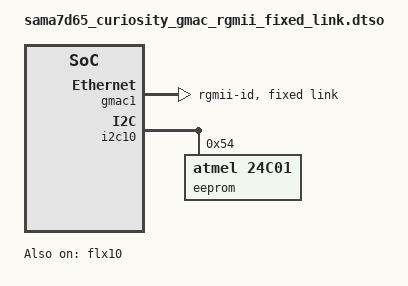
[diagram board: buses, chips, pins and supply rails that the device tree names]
// SPDX-License-Identifier: (GPL-2.0+ OR MIT)
/*
 *  Device Tree overlay for SAMA7D65-CURIOSITY board
 *  in order to use single-port Gigabit PHY EDS2 daughter card.
 *
 *  Copyright (c) 2026 Microchip Technology Inc. and its subsidiaries
 *
 *  Author: Joemel John Diente <joemeljohn.diente@microchip.com>
 *
 * Refer to the EV12N54A (LAN8840-EDS2 daughter card)
 *
 */
/dts-v1/;
/plugin/;
#include "sama7d65-pinfunc.h"
#include <dt-bindings/mfd/atmel-flexcom.h>
#include <dt-bindings/clock/at91.h>
#include <dt-bindings/pinctrl/at91.h>
#include <dt-bindings/gpio/gpio.h>
#include <dt-bindings/interrupt-controller/irq.h>

&{/}
{
	model = "Microchip SAMA7D65 Curiosity Fixed Link RGMII";
};

&flx10 {
	atmel,flexcom-mode = <ATMEL_FLEXCOM_MODE_TWI>;
	status = "okay";
};

&gmac1 {
	#address-cells = <1>;
	#size-cells = <0>;
	phy-mode = "rgmii-id";
	status = "okay";

	// Fix MAC at 1000Mbps
	fixed-link {
		speed = <1000>;
		full-duplex;
	};

	// Add mdio to appear in mdio-tools
	mdio {
		#address-cells = <1>;
		#size-cells = <0>;

		// Make sure disabled status of PHY connected to EDS2 to avoid loading drivers. 
		// In this case, PHYAD = 1 because of @1 & reg = <1>;
		ethernet-phy@1 {
			reg = <1>;
			status = "disabled";
		};
	};
};

&flx10 {
	atmel,flexcom-mode = <ATMEL_FLEXCOM_MODE_TWI>;
	status = "okay";
};

&i2c10 {
	#address-cells = <1>;
	#size-cells = <0>;
	dmas = <0>, <0>;
	status = "okay";

	eeprom@54 {
		compatible = "atmel,24c01";
		reg = <0x54>;
		pagesize = <8>;
		status = "okay";
	};
};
